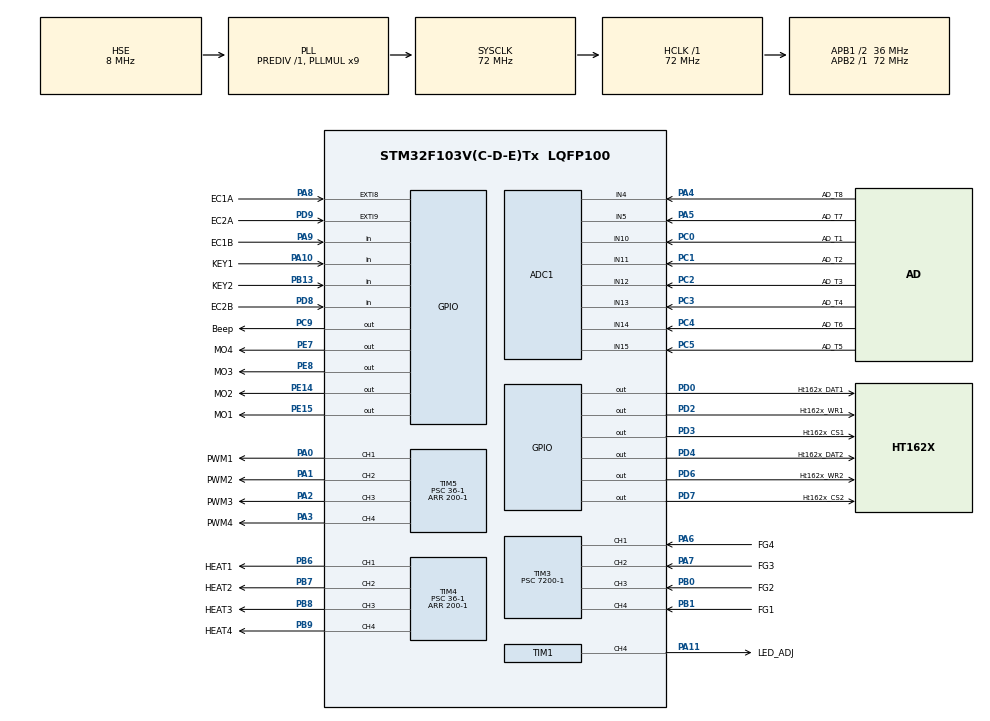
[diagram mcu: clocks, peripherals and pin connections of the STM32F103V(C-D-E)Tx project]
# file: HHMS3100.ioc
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ADC1.Channel-0\#ChannelRegularConversion=ADC_CHANNEL_10
ADC1.Channel-1\#ChannelRegularConversion=ADC_CHANNEL_11
ADC1.Channel-2\#ChannelRegularConversion=ADC_CHANNEL_12
ADC1.Channel-3\#ChannelRegularConversion=ADC_CHANNEL_13
ADC1.Channel-4\#ChannelRegularConversion=ADC_CHANNEL_15
ADC1.Channel-5\#ChannelRegularConversion=ADC_CHANNEL_14
ADC1.Channel-6\#ChannelRegularConversion=ADC_CHANNEL_5
ADC1.Channel-7\#ChannelRegularConversion=ADC_CHANNEL_4
ADC1.ContinuousConvMode=ENABLE
ADC1.ExternalTrigConv=ADC_SOFTWARE_START
ADC1.NbrOfConversion=8
ADC1.NbrOfConversionFlag=1
ADC1.Rank-0\#ChannelRegularConversion=1
ADC1.Rank-1\#ChannelRegularConversion=2
ADC1.Rank-2\#ChannelRegularConversion=3
ADC1.Rank-3\#ChannelRegularConversion=4
ADC1.Rank-4\#ChannelRegularConversion=5
ADC1.Rank-5\#ChannelRegularConversion=6
ADC1.Rank-6\#ChannelRegularConversion=7
ADC1.Rank-7\#ChannelRegularConversion=8
ADC1.SamplingTime-0\#ChannelRegularConversion=ADC_SAMPLETIME_239CYCLES_5
ADC1.SamplingTime-1\#ChannelRegularConversion=ADC_SAMPLETIME_239CYCLES_5
ADC1.SamplingTime-2\#ChannelRegularConversion=ADC_SAMPLETIME_239CYCLES_5
ADC1.SamplingTime-3\#ChannelRegularConversion=ADC_SAMPLETIME_239CYCLES_5
ADC1.SamplingTime-4\#ChannelRegularConversion=ADC_SAMPLETIME_239CYCLES_5
ADC1.SamplingTime-5\#ChannelRegularConversion=ADC_SAMPLETIME_239CYCLES_5
ADC1.SamplingTime-6\#ChannelRegularConversion=ADC_SAMPLETIME_239CYCLES_5
ADC1.SamplingTime-7\#ChannelRegularConversion=ADC_SAMPLETIME_239CYCLES_5
ADC1.master=1
Dma.ADC1.0.Direction=DMA_PERIPH_TO_MEMORY
Dma.ADC1.0.Instance=DMA1_Channel1
Dma.ADC1.0.MemDataAlignment=DMA_MDATAALIGN_HALFWORD
Dma.ADC1.0.MemInc=DMA_MINC_ENABLE
Dma.ADC1.0.Mode=DMA_CIRCULAR
Dma.ADC1.0.PeriphDataAlignment=DMA_PDATAALIGN_HALFWORD
Dma.ADC1.0.PeriphInc=DMA_PINC_DISABLE
Dma.ADC1.0.Priority=DMA_PRIORITY_HIGH
Dma.Request0=ADC1
Mcu.Family=STM32F1
Mcu.Name=STM32F103V(C-D-E)Tx
Mcu.Package=LQFP100
NVIC.DMA1_Channel1_IRQn=true\:0\:0\:false\:false\:true\:false\:true\:true
NVIC.EXTI9_5_IRQn=true\:6\:0\:true\:false\:true\:true\:true\:true
NVIC.PriorityGroup=NVIC_PRIORITYGROUP_4
NVIC.TIM3_IRQn=true\:5\:0\:true\:false\:true\:true\:true\:true
OSC_IN.Mode=HSE-External-Oscillator
OSC_IN.Signal=RCC_OSC_IN
OSC_OUT.Mode=HSE-External-Oscillator
OSC_OUT.Signal=RCC_OSC_OUT
PA0-WKUP.GPIO_Label=PWM1
PA0-WKUP.Signal=S_TIM5_CH1
PA1.GPIO_Label=PWM2
PA1.Signal=S_TIM5_CH2
PA10.GPIO_Label=KEY1
PA10.Signal=GPIO_Input
PA11.GPIO_Label=LED_ADJ
PA11.Signal=S_TIM1_CH4
PA13.Mode=Serial_Wire
PA13.Signal=SYS_JTMS-SWDIO
PA14.Mode=Serial_Wire
PA14.Signal=SYS_JTCK-SWCLK
PA2.GPIO_Label=PWM3
PA2.Signal=S_TIM5_CH3
PA3.GPIO_Label=PWM4
PA3.Signal=S_TIM5_CH4
PA4.GPIO_Label=AD_T8
PA4.Signal=ADCx_IN4
PA5.GPIO_Label=AD_T7
PA5.Signal=ADCx_IN5
PA6.GPIO_Label=FG4
PA6.Signal=S_TIM3_CH1
PA7.GPIO_Label=FG3
PA7.Signal=S_TIM3_CH2
PA8.GPIO_Label=EC1A
PA8.Signal=GPXTI8
PA9.GPIO_Label=EC1B
PA9.Signal=GPIO_Input
PB0.GPIO_Label=FG2
PB0.Signal=S_TIM3_CH3
PB1.GPIO_Label=FG1
PB1.Signal=S_TIM3_CH4
PB13.GPIO_Label=KEY2
PB13.Signal=GPIO_Input
PB6.GPIO_Label=HEAT1
PB6.Signal=S_TIM4_CH1
PB7.GPIO_Label=HEAT2
PB7.Signal=S_TIM4_CH2
PB8.GPIO_Label=HEAT3
PB8.Signal=S_TIM4_CH3
PB9.GPIO_Label=HEAT4
PB9.Signal=S_TIM4_CH4
PC0.GPIO_Label=AD_T1
PC0.Signal=ADCx_IN10
PC1.GPIO_Label=AD_T2
PC1.Signal=ADCx_IN11
PC2.GPIO_Label=AD_T3
PC2.Signal=ADCx_IN12
PC3.GPIO_Label=AD_T4
PC3.Signal=ADCx_IN13
PC4.GPIO_Label=AD_T6
PC4.Signal=ADCx_IN14
PC5.GPIO_Label=AD_T5
PC5.Signal=ADCx_IN15
PC9.GPIO_Label=Beep
PC9.Signal=GPIO_Output
PD0.GPIO_Label=Ht162x_DAT1
PD0.GPIO_PuPd=GPIO_PULLUP
PD0.GPIO_Speed=GPIO_SPEED_FREQ_HIGH
PD0.PinState=GPIO_PIN_SET
PD0.Signal=GPIO_Output
PD2.GPIO_Label=Ht162x_WR1
PD2.GPIO_PuPd=GPIO_PULLUP
PD2.GPIO_Speed=GPIO_SPEED_FREQ_HIGH
PD2.PinState=GPIO_PIN_SET
PD2.Signal=GPIO_Output
PD3.GPIO_Label=Ht162x_CS1
PD3.GPIO_PuPd=GPIO_PULLUP
PD3.GPIO_Speed=GPIO_SPEED_FREQ_HIGH
PD3.PinState=GPIO_PIN_SET
PD3.Signal=GPIO_Output
PD4.GPIO_Label=Ht162x_DAT2
PD4.GPIO_PuPd=GPIO_PULLUP
PD4.GPIO_Speed=GPIO_SPEED_FREQ_HIGH
PD4.PinState=GPIO_PIN_SET
PD4.Signal=GPIO_Output
PD6.GPIO_Label=Ht162x_WR2
PD6.GPIO_ModeDefaultOutputPP=GPIO_MODE_OUTPUT_PP
PD6.GPIO_PuPd=GPIO_PULLUP
PD6.GPIO_Speed=GPIO_SPEED_FREQ_HIGH
PD6.PinState=GPIO_PIN_SET
PD6.Signal=GPIO_Output
PD7.GPIO_Label=Ht162x_CS2
PD7.GPIO_ModeDefaultOutputPP=GPIO_MODE_OUTPUT_PP
PD7.GPIO_PuPd=GPIO_PULLUP
PD7.GPIO_Speed=GPIO_SPEED_FREQ_HIGH
PD7.PinState=GPIO_PIN_SET
PD7.Signal=GPIO_Output
PD8.GPIO_Label=EC2B
PD8.Signal=GPIO_Input
PD9.GPIO_Label=EC2A
PD9.GPIO_ModeDefaultEXTI=GPIO_MODE_IT_RISING
PD9.Signal=GPXTI9
PE14.GPIO_Label=MO2
PE14.Signal=GPIO_Output
PE15.GPIO_Label=MO1
PE15.Signal=GPIO_Output
PE7.GPIO_Label=MO4
PE7.Signal=GPIO_Output
PE8.GPIO_Label=MO3
PE8.Signal=GPIO_Output
ProjectManager.HeapSize=0x200
ProjectManager.StackSize=0x400
ProjectManager.TargetToolchain=MDK-ARM V5.32
RCC.ADCPresc=RCC_ADCPCLK2_DIV6
RCC.AHBFreq_Value=72000000
RCC.APB1CLKDivider=RCC_HCLK_DIV2
RCC.APB1Freq_Value=36000000
RCC.APB1TimFreq_Value=72000000
RCC.APB2Freq_Value=72000000
RCC.APB2TimFreq_Value=72000000
RCC.HCLKFreq_Value=72000000
RCC.PLLMUL=RCC_PLL_MUL9
RCC.PLLSourceVirtual=RCC_PLLSOURCE_HSE
RCC.SYSCLKFreq_VALUE=72000000
RCC.SYSCLKSource=RCC_SYSCLKSOURCE_PLLCLK
RCC.USBFreq_Value=72000000
SH.ADCx_IN10.0=ADC1_IN10,IN10
SH.ADCx_IN11.0=ADC1_IN11,IN11
SH.ADCx_IN12.0=ADC1_IN12,IN12
SH.ADCx_IN13.0=ADC1_IN13,IN13
SH.ADCx_IN14.0=ADC1_IN14,IN14
SH.ADCx_IN15.0=ADC1_IN15,IN15
SH.ADCx_IN4.0=ADC1_IN4,IN4
SH.ADCx_IN5.0=ADC1_IN5,IN5
SH.S_TIM1_CH4.0=TIM1_CH4,PWM Generation4 CH4
SH.S_TIM3_CH1.0=TIM3_CH1,Input_Capture1_from_TI1
SH.S_TIM3_CH2.0=TIM3_CH2,Input_Capture2_from_TI2
SH.S_TIM3_CH3.0=TIM3_CH3,Input_Capture3_from_TI3
SH.S_TIM3_CH4.0=TIM3_CH4,Input_Capture4_from_TI4
SH.S_TIM4_CH1.0=TIM4_CH1,PWM Generation1 CH1
SH.S_TIM4_CH2.0=TIM4_CH2,PWM Generation2 CH2
SH.S_TIM4_CH3.0=TIM4_CH3,PWM Generation3 CH3
SH.S_TIM4_CH4.0=TIM4_CH4,PWM Generation4 CH4
SH.S_TIM5_CH1.0=TIM5_CH1,PWM Generation1 CH1
SH.S_TIM5_CH2.0=TIM5_CH2,PWM Generation2 CH2
SH.S_TIM5_CH3.0=TIM5_CH3,PWM Generation3 CH3
SH.S_TIM5_CH4.0=TIM5_CH4,PWM Generation4 CH4
TIM1.Channel-PWM\ Generation4\ CH4=TIM_CHANNEL_4
TIM1.OCPolarity_4=TIM_OCPOLARITY_HIGH
TIM1.Period=200-1
TIM1.Prescaler=36-1
TIM3.Channel-Input_Capture1_from_TI1=TIM_CHANNEL_1
TIM3.Channel-Input_Capture2_from_TI2=TIM_CHANNEL_2
TIM3.Channel-Input_Capture3_from_TI3=TIM_CHANNEL_3
TIM3.Channel-Input_Capture4_from_TI4=TIM_CHANNEL_4
TIM3.ICFilter_CH1=8
TIM3.ICFilter_CH2=8
TIM3.ICFilter_CH3=8
TIM3.ICFilter_CH4=8
TIM3.Prescaler=7200-1
TIM4.Channel-PWM\ Generation1\ CH1=TIM_CHANNEL_1
TIM4.Channel-PWM\ Generation2\ CH2=TIM_CHANNEL_2
TIM4.Channel-PWM\ Generation3\ CH3=TIM_CHANNEL_3
TIM4.Channel-PWM\ Generation4\ CH4=TIM_CHANNEL_4
TIM4.OCPolarity_1=TIM_OCPOLARITY_LOW
TIM4.OCPolarity_2=TIM_OCPOLARITY_LOW
TIM4.OCPolarity_3=TIM_OCPOLARITY_LOW
TIM4.OCPolarity_4=TIM_OCPOLARITY_LOW
TIM4.Period=200-1
TIM4.Prescaler=36-1
TIM5.Channel-PWM\ Generation1\ CH1=TIM_CHANNEL_1
TIM5.Channel-PWM\ Generation2\ CH2=TIM_CHANNEL_2
TIM5.Channel-PWM\ Generation3\ CH3=TIM_CHANNEL_3
TIM5.Channel-PWM\ Generation4\ CH4=TIM_CHANNEL_4
TIM5.Period=200-1
TIM5.Prescaler=36-1
board=custom

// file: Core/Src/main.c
/* USER CODE BEGIN Header */
/**
  ******************************************************************************
  * @file           : main.c
  * @brief          : Main program body
  ******************************************************************************
  * @attention
  *
  * Copyright (c) 2024 STMicroelectronics.
  * All rights reserved.
  *
  * This software is licensed under terms that can be found in the LICENSE file
  * in the root directory of this software component.
  * If no LICENSE file comes with this software, it is provided AS-IS.
  *
  ******************************************************************************
  */
/* USER CODE END Header */
#include "main.h"
#include "adc.h"
#include "dma.h"
#include "tim.h"
#include "gpio.h"

/* USER CODE BEGIN Includes */
#include "SEGGER_SYSVIEW.h"
/* USER CODE END Includes */

void SystemClock_Config(void);

int main(void)
{

  /* MCU Configuration--------------------------------------------------------*/

  /* Reset of all peripherals, Initializes the Flash interface and the Systick. */
  HAL_Init();

  /* Configure the system clock */
  SystemClock_Config();

  /* Initialize all configured peripherals */
  MX_GPIO_Init();
  MX_DMA_Init();
  MX_ADC1_Init();
  MX_TIM1_Init();
  MX_TIM3_Init();
  MX_TIM4_Init();
  MX_TIM5_Init();
  /* USER CODE BEGIN 2 */
  SEGGER_SYSVIEW_Conf();
    System_Init();
  /* USER CODE END 2 */

  /* Infinite loop */
  while (1)
  {

  }
}

void SystemClock_Config(void)
{
  RCC_OscInitTypeDef RCC_OscInitStruct = {0};
  RCC_ClkInitTypeDef RCC_ClkInitStruct = {0};
  RCC_PeriphCLKInitTypeDef PeriphClkInit = {0};

  /** Initializes the RCC Oscillators according to the specified parameters
  * in the RCC_OscInitTypeDef structure.
  */
  RCC_OscInitStruct.OscillatorType = RCC_OSCILLATORTYPE_HSE;
  RCC_OscInitStruct.HSEState = RCC_HSE_ON;
  RCC_OscInitStruct.HSEPredivValue = RCC_HSE_PREDIV_DIV1;
  RCC_OscInitStruct.HSIState = RCC_HSI_ON;
  RCC_OscInitStruct.PLL.PLLState = RCC_PLL_ON;
  RCC_OscInitStruct.PLL.PLLSource = RCC_PLLSOURCE_HSE;
  RCC_OscInitStruct.PLL.PLLMUL = RCC_PLL_MUL9;
  if (HAL_RCC_OscConfig(&RCC_OscInitStruct) != HAL_OK)
  {
    Error_Handler();
  }

  /** Initializes the CPU, AHB and APB buses clocks
  */
  RCC_ClkInitStruct.ClockType = RCC_CLOCKTYPE_HCLK|RCC_CLOCKTYPE_SYSCLK
                              |RCC_CLOCKTYPE_PCLK1|RCC_CLOCKTYPE_PCLK2;
  RCC_ClkInitStruct.SYSCLKSource = RCC_SYSCLKSOURCE_PLLCLK;
  RCC_ClkInitStruct.AHBCLKDivider = RCC_SYSCLK_DIV1;
  RCC_ClkInitStruct.APB1CLKDivider = RCC_HCLK_DIV2;
  RCC_ClkInitStruct.APB2CLKDivider = RCC_HCLK_DIV1;

  if (HAL_RCC_ClockConfig(&RCC_ClkInitStruct, FLASH_LATENCY_2) != HAL_OK)
  {
    Error_Handler();
  }
  PeriphClkInit.PeriphClockSelection = RCC_PERIPHCLK_ADC;
  PeriphClkInit.AdcClockSelection = RCC_ADCPCLK2_DIV6;
  if (HAL_RCCEx_PeriphCLKConfig(&PeriphClkInit) != HAL_OK)
  {
    Error_Handler();
  }
}

void Error_Handler(void)
{
  __disable_irq();
  while (1)
  {
  }
}
